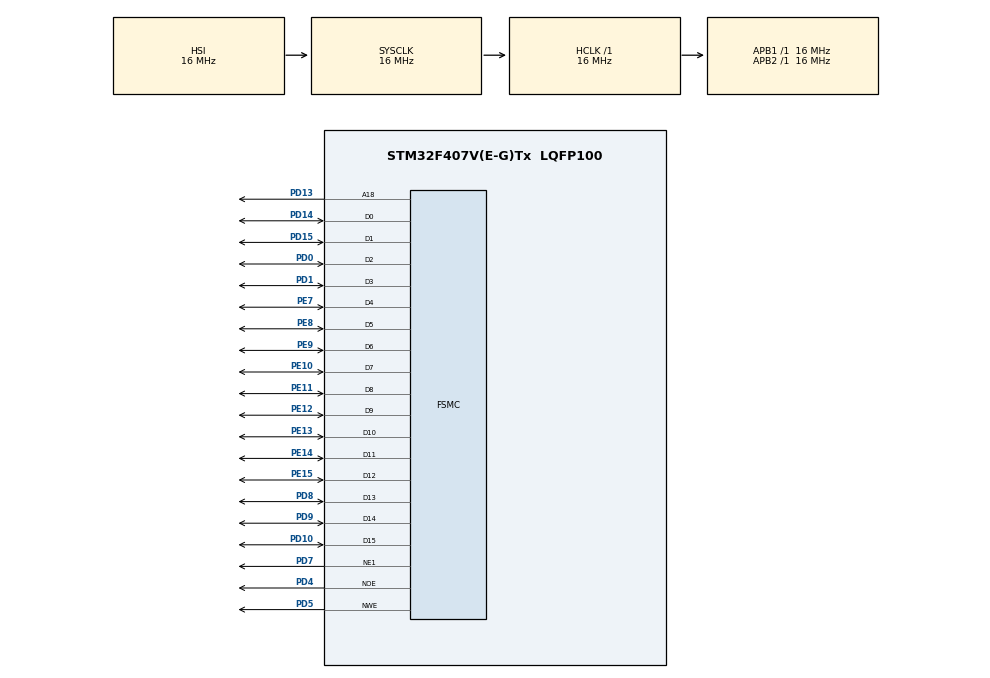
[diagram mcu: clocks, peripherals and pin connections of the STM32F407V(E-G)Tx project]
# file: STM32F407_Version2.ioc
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FSMC.ExtendedMode1=FSMC_EXTENDED_MODE_ENABLE
Mcu.Family=STM32F4
Mcu.Name=STM32F407V(E-G)Tx
Mcu.Package=LQFP100
NVIC.PriorityGroup=NVIC_PRIORITYGROUP_4
PD0.Mode=16b-d1
PD0.Signal=FSMC_D2
PD1.Mode=16b-d1
PD1.Signal=FSMC_D3
PD10.Mode=16b-d1
PD10.Signal=FSMC_D15
PD13.Mode=A18_1
PD13.Signal=FSMC_A18
PD14.Mode=16b-d1
PD14.Signal=FSMC_D0
PD15.Mode=16b-d1
PD15.Signal=FSMC_D1
PD4.Mode=Lcd1
PD4.Signal=FSMC_NOE
PD5.Mode=Lcd1
PD5.Signal=FSMC_NWE
PD7.Mode=NorPsramChipSelect1_1
PD7.Signal=FSMC_NE1
PD8.Mode=16b-d1
PD8.Signal=FSMC_D13
PD9.Mode=16b-d1
PD9.Signal=FSMC_D14
PE10.Mode=16b-d1
PE10.Signal=FSMC_D7
PE11.Mode=16b-d1
PE11.Signal=FSMC_D8
PE12.Mode=16b-d1
PE12.Signal=FSMC_D9
PE13.Mode=16b-d1
PE13.Signal=FSMC_D10
PE14.Mode=16b-d1
PE14.Signal=FSMC_D11
PE15.Mode=16b-d1
PE15.Signal=FSMC_D12
PE7.Mode=16b-d1
PE7.Signal=FSMC_D4
PE8.Mode=16b-d1
PE8.Signal=FSMC_D5
PE9.Mode=16b-d1
PE9.Signal=FSMC_D6
ProjectManager.HeapSize=0x200
ProjectManager.StackSize=0x400
ProjectManager.TargetToolchain=STM32CubeIDE
RCC.AHBFreq_Value=16000000
RCC.APB1Freq_Value=16000000
RCC.APB2Freq_Value=16000000
RCC.CortexFreq_Value=16000000
RCC.HSE_VALUE=25000000
RCC.HSI_VALUE=16000000
RCC.LSE_VALUE=32768
RCC.SYSCLKFreq_VALUE=16000000
RCC.VCOOutputFreq_Value=192000000
board=custom

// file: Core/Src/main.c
/* USER CODE BEGIN Header */
/**
  ******************************************************************************
  * @file           : main.c
  * @brief          : Main program body
  ******************************************************************************
  * @attention
  *
  * <h2><center>&copy; Copyright (c) 2021 STMicroelectronics.
  * All rights reserved.</center></h2>
  *
  * This software component is licensed by ST under BSD 3-Clause license,
  * the "License"; You may not use this file except in compliance with the
  * License. You may obtain a copy of the License at:
  *                        opensource.org/licenses/BSD-3-Clause
  *
  ******************************************************************************
  */
/* USER CODE END Header */
#include "main.h"

/* USER CODE BEGIN Includes */
#include "lcd.h"
/* USER CODE END Includes */

SRAM_HandleTypeDef hsram1;

void SystemClock_Config(void);
static void MX_GPIO_Init(void);
static void MX_FSMC_Init(void);

int main(void)
{
  /* USER CODE BEGIN 1 */
	int x= 0;
  /* USER CODE END 1 */

  /* MCU Configuration--------------------------------------------------------*/

  /* Reset of all peripherals, Initializes the Flash interface and the Systick. */
  HAL_Init();

  /* Configure the system clock */
  SystemClock_Config();

  /* Initialize all configured peripherals */
  MX_GPIO_Init();
  MX_FSMC_Init();
  /* USER CODE BEGIN 2 */

  LCD_Init();

  /* USER CODE END 2 */

  /* Infinite loop */
  while (1)
  {
		switch(x)
		{
			case 0:LCD_Clear(WHITE);break;
			case 1:LCD_Clear(BLACK);break;
			case 2:LCD_Clear(BLUE);break;
			case 3:LCD_Clear(RED);break;
			case 4:LCD_Clear(MAGENTA);break;
			case 5:LCD_Clear(GREEN);break;
			case 6:LCD_Clear(CYAN);break;
			case 7:LCD_Clear(YELLOW);break;
			case 8:LCD_Clear(BRRED);break;
			case 9:LCD_Clear(GRAY);break;
			case 10:LCD_Clear(LGRAY);break;
			case 11:LCD_Clear(BROWN);break;
		}
		POINT_COLOR=RED;
		LCD_ShowString(30,40,210,24,24,"STM32F4");
		LCD_ShowString(30,70,200,16,16,"TFTLCD TEST");
		LCD_ShowString(30,90,200,16,16,"www.csun.co.jp");
		LCD_ShowString(30,110,200,16,16,"LCD: ILI9431");
		LCD_ShowString(30,130,200,12,12,"2015/08/04");
	    x++;
	    if (x>11)
	    	x=0;
	    delay_us(1000000);

  }
}

void SystemClock_Config(void)
{
  RCC_OscInitTypeDef RCC_OscInitStruct = {0};
  RCC_ClkInitTypeDef RCC_ClkInitStruct = {0};

  /** Configure the main internal regulator output voltage
  */
  __HAL_RCC_PWR_CLK_ENABLE();
  __HAL_PWR_VOLTAGESCALING_CONFIG(PWR_REGULATOR_VOLTAGE_SCALE1);
  /** Initializes the RCC Oscillators according to the specified parameters
  * in the RCC_OscInitTypeDef structure.
  */
  RCC_OscInitStruct.OscillatorType = RCC_OSCILLATORTYPE_HSI;
  RCC_OscInitStruct.HSIState = RCC_HSI_ON;
  RCC_OscInitStruct.HSICalibrationValue = RCC_HSICALIBRATION_DEFAULT;
  RCC_OscInitStruct.PLL.PLLState = RCC_PLL_NONE;
  if (HAL_RCC_OscConfig(&RCC_OscInitStruct) != HAL_OK)
  {
    Error_Handler();
  }
  /** Initializes the CPU, AHB and APB buses clocks
  */
  RCC_ClkInitStruct.ClockType = RCC_CLOCKTYPE_HCLK|RCC_CLOCKTYPE_SYSCLK
                              |RCC_CLOCKTYPE_PCLK1|RCC_CLOCKTYPE_PCLK2;
  RCC_ClkInitStruct.SYSCLKSource = RCC_SYSCLKSOURCE_HSI;
  RCC_ClkInitStruct.AHBCLKDivider = RCC_SYSCLK_DIV1;
  RCC_ClkInitStruct.APB1CLKDivider = RCC_HCLK_DIV1;
  RCC_ClkInitStruct.APB2CLKDivider = RCC_HCLK_DIV1;

  if (HAL_RCC_ClockConfig(&RCC_ClkInitStruct, FLASH_LATENCY_0) != HAL_OK)
  {
    Error_Handler();
  }
}

static void MX_GPIO_Init(void)
{

  /* GPIO Ports Clock Enable */
  __HAL_RCC_GPIOE_CLK_ENABLE();
  __HAL_RCC_GPIOD_CLK_ENABLE();

}

/* FSMC initialization function */
static void MX_FSMC_Init(void)
{

  FSMC_NORSRAM_TimingTypeDef Timing = {0};
  FSMC_NORSRAM_TimingTypeDef ExtTiming = {0};

  /** Perform the SRAM1 memory initialization sequence
  */
  hsram1.Instance = FSMC_NORSRAM_DEVICE;
  hsram1.Extended = FSMC_NORSRAM_EXTENDED_DEVICE;
  /* hsram1.Init */
  hsram1.Init.NSBank = FSMC_NORSRAM_BANK1;
  hsram1.Init.DataAddressMux = FSMC_DATA_ADDRESS_MUX_DISABLE;
  hsram1.Init.MemoryType = FSMC_MEMORY_TYPE_SRAM;
  hsram1.Init.MemoryDataWidth = FSMC_NORSRAM_MEM_BUS_WIDTH_16;
  hsram1.Init.BurstAccessMode = FSMC_BURST_ACCESS_MODE_DISABLE;
  hsram1.Init.WaitSignalPolarity = FSMC_WAIT_SIGNAL_POLARITY_LOW;
  hsram1.Init.WrapMode = FSMC_WRAP_MODE_DISABLE;
  hsram1.Init.WaitSignalActive = FSMC_WAIT_TIMING_BEFORE_WS;
  hsram1.Init.WriteOperation = FSMC_WRITE_OPERATION_ENABLE;
  hsram1.Init.WaitSignal = FSMC_WAIT_SIGNAL_DISABLE;
  hsram1.Init.ExtendedMode = FSMC_EXTENDED_MODE_ENABLE;
  hsram1.Init.AsynchronousWait = FSMC_ASYNCHRONOUS_WAIT_DISABLE;
  hsram1.Init.WriteBurst = FSMC_WRITE_BURST_DISABLE;
  hsram1.Init.PageSize = FSMC_PAGE_SIZE_NONE;
  /* Timing */
  Timing.AddressSetupTime = 8;
  Timing.AddressHoldTime = 0;
  Timing.DataSetupTime = 8;
  Timing.BusTurnAroundDuration = 0;
  Timing.CLKDivision = 0;
  Timing.DataLatency = 0;
  Timing.AccessMode = FSMC_ACCESS_MODE_A;
  /* ExtTiming */
  ExtTiming.AddressSetupTime = 8;
  ExtTiming.AddressHoldTime = 0;
  ExtTiming.DataSetupTime = 8;
  ExtTiming.BusTurnAroundDuration = 0;
  ExtTiming.CLKDivision = 0;
  ExtTiming.DataLatency = 0;
  ExtTiming.AccessMode = FSMC_ACCESS_MODE_A;

  if (HAL_SRAM_Init(&hsram1, &Timing, &ExtTiming) != HAL_OK)
  {
    Error_Handler( );
  }

}

void Error_Handler(void)
{
  __disable_irq();
  while (1)
  {
  }
}

/************************ (C) COPYRIGHT STMicroelectronics *****END OF FILE****/
